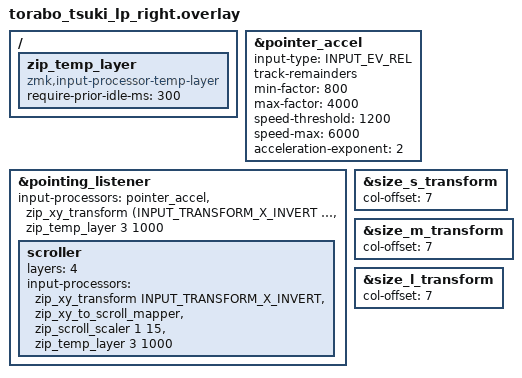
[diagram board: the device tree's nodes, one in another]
#include "torabo_tsuki_lp.dtsi"
#include <input/processors.dtsi>
#include <dt-bindings/zmk/input_transform.h>
#include <behaviors/input_gestures_accel.dtsi>

/ {
    /omit-if-no-ref/ zip_temp_layer: zip_temp_layer {
        compatible = "zmk,input-processor-temp-layer";
        require-prior-idle-ms = <300>;
    };
};

&pointer_accel {
    input-type = <INPUT_EV_REL>;  // For relative input devices
    track-remainders;             // Accumulate fractional movements
    min-factor = <800>;          // 0.8x at very slow speeds
    max-factor = <4000>;         // 3.0x at fast speeds
    speed-threshold = <1200>;     // 1200 counts/sec for 1x
    speed-max = <6000>;          // 6000 counts/sec for max accel
    acceleration-exponent = <2>;  // Quadratic acceleration curve
};

&pointing_listener {
    input-processors =
        <&pointer_accel>,
        <&zip_xy_transform (INPUT_TRANSFORM_X_INVERT | INPUT_TRANSFORM_Y_INVERT)>,
        <&zip_temp_layer 3 1000>;

    scroller {
        layers = <4>;
        input-processors =
            <&zip_xy_transform INPUT_TRANSFORM_X_INVERT>,
            <&zip_xy_to_scroll_mapper>,
            <&zip_scroll_scaler 1 15>,
            <&zip_temp_layer 3 1000>;
    };
};

&size_s_transform {
    col-offset = <7>;
};

&size_m_transform {
    col-offset = <7>;
};

&size_l_transform {
    col-offset = <7>;
};
